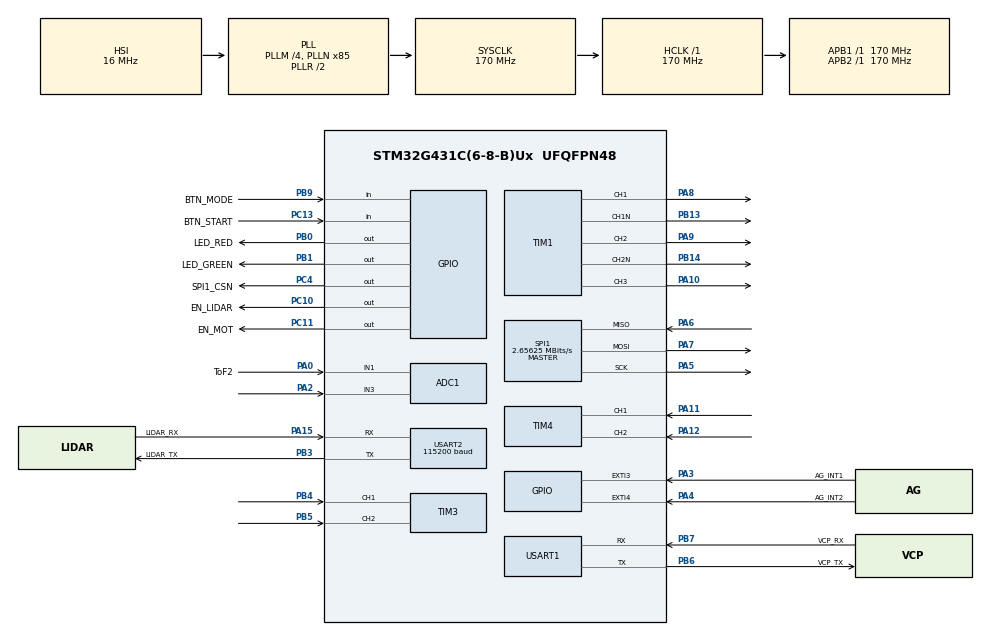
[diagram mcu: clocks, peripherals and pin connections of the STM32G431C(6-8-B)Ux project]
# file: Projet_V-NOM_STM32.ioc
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ADC1.Channel-1\#ChannelRegularConversion=ADC_CHANNEL_3
ADC1.ContinuousConvMode=ENABLE
ADC1.DMAContinuousRequests=DISABLE
ADC1.NbrOfConversion=1
ADC1.NbrOfConversionFlag=1
ADC1.OffsetNumber-1\#ChannelRegularConversion=ADC_OFFSET_NONE
ADC1.Rank-1\#ChannelRegularConversion=1
ADC1.SamplingTime-1\#ChannelRegularConversion=ADC_SAMPLETIME_2CYCLES_5
ADC1.master=1
Dma.Request0=USART2_RX
Dma.USART2_RX.0.Direction=DMA_PERIPH_TO_MEMORY
Dma.USART2_RX.0.EventEnable=DISABLE
Dma.USART2_RX.0.Instance=DMA1_Channel1
Dma.USART2_RX.0.MemDataAlignment=DMA_MDATAALIGN_BYTE
Dma.USART2_RX.0.MemInc=DMA_MINC_ENABLE
Dma.USART2_RX.0.Mode=DMA_CIRCULAR
Dma.USART2_RX.0.PeriphDataAlignment=DMA_PDATAALIGN_BYTE
Dma.USART2_RX.0.PeriphInc=DMA_PINC_DISABLE
Dma.USART2_RX.0.Polarity=HAL_DMAMUX_REQ_GEN_RISING
Dma.USART2_RX.0.Priority=DMA_PRIORITY_VERY_HIGH
Dma.USART2_RX.0.RequestNumber=1
Dma.USART2_RX.0.SignalID=NONE
Dma.USART2_RX.0.SyncEnable=DISABLE
Dma.USART2_RX.0.SyncPolarity=HAL_DMAMUX_SYNC_NO_EVENT
Dma.USART2_RX.0.SyncRequestNumber=1
Dma.USART2_RX.0.SyncSignalID=NONE
FREERTOS.Tasks01=defaultTask,0,128,StartDefaultTask,Default,NULL,Dynamic,NULL,NULL
FREERTOS.configTOTAL_HEAP_SIZE=10 * 1024
FREERTOS.configUSE_NEWLIB_REENTRANT=1
Mcu.Family=STM32G4
Mcu.Name=STM32G431C(6-8-B)Ux
Mcu.Package=UFQFPN48
NVIC.DMA1_Channel1_IRQn=true\:5\:0\:false\:false\:true\:true\:false\:true\:true
NVIC.PriorityGroup=NVIC_PRIORITYGROUP_4
NVIC.SPI1_IRQn=true\:5\:0\:false\:false\:true\:true\:true\:true\:true
NVIC.TIM2_IRQn=true\:15\:0\:false\:false\:true\:false\:false\:true\:true
NVIC.TimeBase=TIM2_IRQn
NVIC.TimeBaseIP=TIM2
NVIC.USART2_IRQn=true\:5\:0\:false\:false\:true\:true\:true\:true\:true
PA0.GPIO_Label=ToF2
PA0.Signal=SharedAnalog_PA0
PA10.Signal=S_TIM1_CH3
PA11.Signal=S_TIM4_CH1
PA12.Signal=S_TIM4_CH2
PA13.Mode=Serial_Wire
PA13.Signal=SYS_JTMS-SWDIO
PA14.Mode=Serial_Wire
PA14.Signal=SYS_JTCK-SWCLK
PA15.GPIO_Label=LIDAR_RX
PA15.Mode=Asynchronous
PA15.Signal=USART2_RX
PA2.Mode=IN3-Single-Ended
PA2.Signal=ADC1_IN3
PA3.GPIO_Label=AG_INT1
PA3.Signal=GPXTI3
PA4.GPIO_Label=AG_INT2
PA4.Signal=GPXTI4
PA5.Mode=Full_Duplex_Master
PA5.Signal=SPI1_SCK
PA6.Mode=Full_Duplex_Master
PA6.Signal=SPI1_MISO
PA7.Mode=Full_Duplex_Master
PA7.Signal=SPI1_MOSI
PA8.Signal=S_TIM1_CH1
PA9.Signal=S_TIM1_CH2
PB0.GPIO_Label=LED_RED
PB0.Signal=GPIO_Output
PB1.GPIO_Label=LED_GREEN
PB1.Signal=GPIO_Output
PB13.Mode=PWM Generation1 CH1 CH1N
PB13.Signal=TIM1_CH1N
PB14.Mode=PWM Generation2 CH2 CH2N
PB14.Signal=TIM1_CH2N
PB3.GPIO_Label=LIDAR_TX
PB3.Mode=Asynchronous
PB3.Signal=USART2_TX
PB4.Signal=S_TIM3_CH1
PB5.Signal=S_TIM3_CH2
PB6.GPIO_Label=VCP_TX
PB6.Mode=Asynchronous
PB6.Signal=USART1_TX
PB7.GPIO_Label=VCP_RX
PB7.Mode=Asynchronous
PB7.Signal=USART1_RX
PB9.GPIO_Label=BTN_MODE
PB9.Signal=GPIO_Input
PC10.GPIO_Label=EN_LIDAR
PC10.Signal=GPIO_Output
PC11.GPIO_Label=EN_MOT
PC11.Signal=GPIO_Output
PC13.GPIO_Label=BTN_START
PC13.Signal=GPIO_Input
PC14-OSC32_IN.Mode=LSE-External-Oscillator
PC14-OSC32_IN.Signal=RCC_OSC32_IN
PC15-OSC32_OUT.Mode=LSE-External-Oscillator
PC15-OSC32_OUT.Signal=RCC_OSC32_OUT
PC4.GPIO_Label=SPI1_CSN
PC4.Signal=GPIO_Output
PF0-OSC_IN.Mode=HSE-External-Oscillator
PF0-OSC_IN.Signal=RCC_OSC_IN
PF1-OSC_OUT.Mode=HSE-External-Oscillator
PF1-OSC_OUT.Signal=RCC_OSC_OUT
ProjectManager.HeapSize=0x200
ProjectManager.StackSize=0x400
ProjectManager.TargetToolchain=STM32CubeIDE
RCC.ADC12Freq_Value=170000000
RCC.AHBFreq_Value=170000000
RCC.APB1Freq_Value=170000000
RCC.APB1TimFreq_Value=170000000
RCC.APB2Freq_Value=170000000
RCC.APB2TimFreq_Value=170000000
RCC.CortexFreq_Value=170000000
RCC.EXTERNAL_CLOCK_VALUE=12288000
RCC.HCLKFreq_Value=170000000
RCC.HSE_VALUE=16000000
RCC.HSI48_VALUE=48000000
RCC.HSI_VALUE=16000000
RCC.PLLM=RCC_PLLM_DIV4
RCC.PLLN=85
RCC.SYSCLKFreq_VALUE=170000000
RCC.SYSCLKSource=RCC_SYSCLKSOURCE_PLLCLK
RCC.USBFreq_Value=170000000
RCC.VCOOutputFreq_Value=340000000
SH.S_TIM1_CH1.0=TIM1_CH1,PWM Generation1 CH1 CH1N
SH.S_TIM1_CH2.0=TIM1_CH2,PWM Generation2 CH2 CH2N
SH.S_TIM1_CH3.0=TIM1_CH3,PWM Generation3 CH3
SH.S_TIM3_CH1.0=TIM3_CH1,Encoder_Interface
SH.S_TIM3_CH2.0=TIM3_CH2,Encoder_Interface
SH.S_TIM4_CH1.0=TIM4_CH1,Encoder_Interface
SH.S_TIM4_CH2.0=TIM4_CH2,Encoder_Interface
SH.SharedAnalog_PA0.0=GPIO_Analog
SH.SharedAnalog_PA0.1=ADC2_IN1
SH.SharedAnalog_PA0.2=ADC1_IN1,IN1-Single-Ended
SPI1.BaudRatePrescaler=SPI_BAUDRATEPRESCALER_64
SPI1.CalculateBaudRate=2.65625 MBits/s
SPI1.DataSize=SPI_DATASIZE_8BIT
SPI1.Direction=SPI_DIRECTION_2LINES
SPI1.Mode=SPI_MODE_MASTER
SPI1.VirtualType=VM_MASTER
TIM1.Channel-PWM\ Generation1\ CH1\ CH1N=TIM_CHANNEL_1
TIM1.Channel-PWM\ Generation2\ CH2\ CH2N=TIM_CHANNEL_2
TIM1.Channel-PWM\ Generation3\ CH3=TIM_CHANNEL_3
USART1.VirtualMode-Asynchronous=VM_ASYNC
USART2.AutoBaudRateEnableParam=UART_ADVFEATURE_AUTOBAUDRATE_DISABLE
USART2.BaudRate=115200
USART2.ClockPrescaler=PRESCALER_DIV1
USART2.Mode=MODE_RX
USART2.OneBitSampling=UART_ONE_BIT_SAMPLE_DISABLE
USART2.OverSampling=UART_OVERSAMPLING_16
USART2.StopBits=STOPBITS_1
USART2.VirtualMode-Asynchronous=VM_ASYNC
VP_FREERTOS_VS_CMSIS_V1.Mode=CMSIS_V1
VP_SYS_VS_DBSignals.Mode=DisableDeadBatterySignals
VP_SYS_VS_tim2.Mode=TIM2
VP_TIM1_VS_ClockSourceINT.Mode=Internal
board=custom

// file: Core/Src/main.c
/* USER CODE BEGIN Header */
/**
 ******************************************************************************
 * @file           : main.c
 * @brief          : Main program body
 ******************************************************************************
 * @attention
 *
 * Copyright (c) 2024 STMicroelectronics.
 * All rights reserved.
 *
 * This software is licensed under terms that can be found in the LICENSE file
 * in the root directory of this software component.
 * If no LICENSE file comes with this software, it is provided AS-IS.
 *
 ******************************************************************************
 */
/* USER CODE END Header */
#include "main.h"
#include "cmsis_os.h"
#include "adc.h"
#include "dma.h"
#include "spi.h"
#include "tim.h"
#include "usart.h"
#include "gpio.h"

/* USER CODE BEGIN Includes */
#include <stdio.h>
#include <stdlib.h>
#include "stm32g4xx_hal.h"

// Drivers
#include "../drivers/driver_Motor.h"
#include "../drivers/driver_GP2Y0A41SK0F.h"
#include "../drivers/driver_YLIDARX2.h"
#include "../drivers/driver_ADXL343.h"

/* USER CODE END Includes */

/* USER CODE BEGIN PD */
#define DEBUG 1 /**< Enable or disable debug logs */

#if DEBUG
#define DEBUG_PRINT(...) printf(__VA_ARGS__)
#else
#define DEBUG_PRINT(...)
#endif

#define STACK_SIZE 256
#define TASK_PRIORITY_MOTOR 10
#define TASK_PRIORITY_CONTROL 2

#define TOF_TRESHHOLD 40 /**< Threshhold for edge detection */

#define DEBOUNCE_DELAY_MS 50 /**< Debounce delay in milliseconds */

/* USER CODE END PD */

/* USER CODE BEGIN PV */
// Messages
char small_logo_msg[] ="\r\n"
		"       \\_______/\r\n"
		"   `.,-'\\_____/`-.,'\r\n"
		"    /`..'\\ _ /`.,'\\\r\n"
		"   /  /`.,' `.,'\\  \\\r\n"
		"__/__/__/V-NOM\\__\\__\\__\r\n"
		"  \\  \\  \\     /  /  /\r\n"
		"   \\  \\,'`._,'`./  /\r\n"
		"    \\,'`./___\\,'`./\r\n"
		"   ,'`-./_____\\,-'`.\r\n"
		"       /       \\ \r\n";

char big_logo_msg[] = "\r\n"
		"⠀⠀⠀⠀⠀⠀⠀⠀⢀⣀⣤⠤⠶⠶⠶⠤⠤⣤⣀\t\r\n"
		"⠀⠀⠀⠀⢀⣠⠶⠛⠉⠀⠀⠀⠀⠀⠀⠀⠀⠀⠈⠙⠳⢦⣀\t\r\n"
		"⠀⠀⠀⣰⠟⠁⠀⠀⠀⠀⠀⠀⠀⠀⠀⠀⠀⠀⠀⠀⠀⠀⠙⢷⡄\t\r\n"
		"⠀⠀⣰⠏⠀⢠⣶⠀⠀⠀⠀⠀⠀⠀⠀⠀⠀⠀⠀⠀⠀⣤⡀⠀⠹⣆\t\r\n"
		"⠀⢠⡏⠀⢠⠟⣧⠀⠀⠀⠀⠀⠀⠀⠀⠀⠀⠀⠀⠀⠀⣿⢳⡄⠀⢹⡄\t\r\n"
		"⠀⣾⠀⠀⡞⠀⢸⡀⠀⠀⠀⠀⠀⠀⠀⠀⠀⠀⠀⠀⣰⠇⠀⢷⠀⠈⣇\t\r\n"
		"⢠⡇⠀⢠⠇⠀⠀⠙⣆⠀⠀⠀⠀⠀⠀⠀⠀⠀⠀⣰⠋⠀⠀⠸⡆⠀⣿\t\r\n"
		"⢸⡇⠀⢸⠀⠀⠀⠀⠙⢦⡀⠀⠀⠀⠀⠀⠀⢀⡾⠃⠀⠀⠀⢰⠇⠀⣿\t\r\n"
		"⢸⡇⠀⢸⠀⠀⠀⠀⠀⠀⠳⣄⣰⡄⢰⣄⣰⠋⠀⠀⠀⠀⠀⢸⡀⠀⣿\t\r\n"
		"⠘⡇⠀⢸⠀⠀⠀⠀⠀⠀⠀⠈⢹⡇⢸⠉⠁⠀⠀⠀⠀⠀⠀⠈⡇⠀⡟\t\r\n"
		"⠀⢿⠀⠈⢧⡀⠀⠀⠀⠀⠀⠀⣾⠀⢸⣄⠀⠀⠀⠀⠀⠀⠀⡼⢁⢸⡇\t\r\n"
		"⠀⢸⠘⣆⠈⢧⠀⠀⠀⠀⣠⠴⠃⠀⠀⠙⢧⣀⠀⠀⠀⠀⡼⠀⡼⢸⡃⠀⠀⠀⠀⠀⢀\t\r\n"
		"⠀⣾⠀⢸⣆⠘⠷⠤⠴⠚⣁⣀⣤⣤⣤⣄⣀⠉⠙⠲⠴⠚⢡⣾⠇⠘⡇⠀⠀⠀⠀⠀⠈⢷⣤⡀\t\r\n"
		"⠀⢹⣆⠈⣿⣷⣾⡖⣾⠻⣟⣾⣏⣻⣹⡟⡟⣿⢳⣶⣶⣾⣿⡟⠀⢰⡇⠀⠀⠀⠀⠀⠀⠘⣇⢻⡄\t\r\n"
		"⠀⠀⠻⣄⢸⣿⡋⠹⠿⣿⣿⡿⢿⣿⡟⣿⢿⣿⡟⠹⠋⠙⡿⠁⣴⠟⠀⠀⠀⠀⠀⠀⠀⠀⣿⠀⣷\t\r\n"
		"⠀⠀⠀⠹⣶⣿⣿⣄⠀⢻⣘⣦⣼⣿⣴⣿⣼⣼⣇⡀⣰⣿⠃⣴⠏⠀⠀⠀⠀⠀⠀⠀⢀⣴⠏⢀⡏\t\r\n"
		"⠀⠀⠀⠀⠙⣿⢿⣿⣥⣾⠛⠉⠀⠀⠉⠙⢦⡀⠈⠙⢿⣇⣰⠃⠀⠀⠀⠀⣀⣀⡤⠶⠛⠁⢠⡾⠁\t\r\n"
		"⠀⠀⠀⠀⠀⠘⣿⠻⣿⢻⣦⠀⢀⡀⠀⠀⠀⠙⠀⠀⠀⠹⣇⠀⠀⢀⣴⠟⠉⠀⠀⢀⣠⡼⠋\t\r\n"
		"⠀⠀⠀⠀⠀⠀⠘⣿⢹⡾⢻⣇⣴⡿⠳⢦⣀⠀⠀⠀⠀⠀⠙⠳⠶⠛⠁⠀⠀⢀⡼⠋⠁\t\r\n"
		"⠀⠀⠀⠀⠀⠀⠀⠘⣿⠻⡎⢹⢿⣷⣶⣎⣿⣧⡀⠀⠀⠀⠀⠀⠀⠀⠀⠀⢀⡾⠁\t\r\n"
		"⠀⠀⠀⠀⠀⠀⠀⠀⠸⣆⠙⢾⣸⠙⡿⢿⣩⠏⢹⣦⣀⠀⠀⠀⠀⠀⢀⣴⠟⠁\t\r\n"
		"⠀⠀⠀⠀⠀⠀⠀⠀⠀⠹⣦⡀⠉⠉⠉⠉⠁⣰⠏⠀⠈⠉⠛⠒⠒⠛⠉⠁\t\r\n"
		"⠀⠀⠀⠀⠀⠀⠀⠀⠀⠀⠈⠉⠓⠒⠒⠒⠋⠁\t\r\n";

char jumbo_logo_msg[] = "\r\n"
		"⣿⣿⣿⣿⣿⣿⣿⠿⢻⣿⣿⣿⣿⣿⣿⣿⣿⣿⣿⣿⣿⣿⣿⣿⣿⣿⣿⣿⣿⣿⣿⡟⠻⣿⣿⣿⣿⣿⣿⣿\r\n"
		"⣿⣿⣿⣿⣿⠟⠁⢠⣿⣿⣿⣿⣿⣿⣿⣿⣿⣿⣿⣿⣿⣿⣿⣿⣿⣿⣿⣿⣿⣿⣿⡇⠀⠀⠙⣿⣿⣿⣿⣿\r\n"
		"⣿⣿⣿⣿⠃⠀⢀⣿⣿⣿⣿⣿⣿⣿⣿⣿⣿⣿⣿⣿⣿⣿⣿⣿⣿⣿⣿⣿⣿⣿⣿⣷⠀⠀⠀⠈⢻⣿⣿⣿\r\n"
		"⣿⣿⣟⠁⠀⠀⢸⣿⣿⣿⣿⣿⣿⣿⣿⣿⣿⣿⣿⣿⣿⣿⣿⣿⣿⣿⣿⣿⣿⣿⣿⠇⢀⡀⠀⠀⠈⢿⣿⣿\r\n"
		"⣿⣿⡏⠀⠀⠀⢸⣿⣿⣿⣿⣿⣿⣿⣿⣿⣿⣿⣿⣿⣿⣿⣿⣿⣿⣿⣿⣿⣿⣿⣿⣟⣼⣿⠀⠀⠀⠈⣿⣿\r\n"
		"⣿⣿⠀⠀⠀⠀⠸⣿⣿⣿⣿⣿⣿⣿⣿⣿⣿⣿⣿⣿⣿⣿⣿⣿⣿⣿⣿⣿⣿⣿⣿⣿⣿⡏⠀⠀⠀⠀⢹⣿\r\n"
		"⣿⡿⠀⠀⠀⠀⠀⢿⣿⣿⣿⣿⣿⣿⣿⣿⣿⣿⢿⣿⣿⣿⣿⣿⣿⣿⣿⣿⣿⣿⣿⣿⣿⠁⠀⠀⠀⠀⠈⣿\r\n"
		"⣿⡇⠀⠀⠀⠀⠀⠈⠉⠉⣻⣿⡿⣿⣿⣿⣿⢷⣺⣿⣿⣿⣿⣿⣿⣿⣿⣭⣭⣙⣿⠋⠁⠀⠀⠀⠀⠀⠀⣿\r\n"
		"⣿⡷⡶⠀⠀⠀⠀⠀⠀⠈⠋⠛⠻⠿⠿⣿⡟⢿⣿⣿⣿⣿⡿⠿⡿⡿⣿⣻⣿⡿⠁⠀⠀⠀⠀⠀⠀⠀⢸⣿\r\n"
		"⣿⣿⠀⠀⠀⠀⠀⠀⠀⠀⠀⠀⠰⠦⠐⠛⢻⣿⣿⣿⣿⣿⣇⣼⣿⣿⣿⣿⠋⠀⠀⠀⠀⠀⠀⠀⠀⠀⢸⣿\r\n"
		"⣿⣿⡄⠀⠀⠀⠀⠀⠀⠀⠀⠀⠀⠘⣿⣯⣽⣿⣿⣿⣿⣿⣿⣿⣿⣿⣿⠃⠀⠀⠀⠀⠀⠀⠀⠀⠀⠀⢸⣿\r\n"
		"⣿⣿⣇⠀⠀⠀⠀⠀⠀⠀⠀⠀⠀⠀⢸⡟⢿⣿⣿⣿⣿⣿⣿⣿⢃⣿⠇⠀⠀⠀⠀⠀⠀⠀⠀⠀⠀⢀⣿⣿\r\n"
		"⣿⣿⣿⡇⢀⣀⠀⠀⠀⠀⠀⠀⠀⠀⠈⠻⣮⣿⣿⣿⣿⣿⣿⡟⠿⠋⠀⠀⠀⠀⠀⠀⠀⠀⡀⠀⠀⣾⣿⣿\r\n"
		"⣿⣿⣿⡗⠈⣿⣿⣆⠀⠀⠀⠀⠀⠀⠀⠀⢀⡸⣿⣿⣿⣿⡏⠀⠀⠀⠀⠀⠀⠀⠀⠀⣰⣾⣧⡄⢀⣿⣿⣿\r\n"
		"⣿⣿⣿⣿⣤⣿⣿⣿⣷⣄⣀⣴⣶⣶⣶⣤⣄⣹⣿⣿⣿⣿⠀⠀⢀⣀⠶⣄⣀⣤⡶⠾⢿⣿⣿⣷⣿⣿⣿⣿\r\n"
		"⣿⣿⣿⣿⣿⣿⣿⣿⣿⡿⣿⣿⣿⣿⣿⣿⣿⣿⣿⣿⣿⣿⢺⣷⢿⣿⣾⣿⣿⣿⣿⣿⣿⣿⣿⣿⣿⣿⣿⣿\r\n"
		"⣿⣿⣿⣯⣿⠛⠃⣿⢹⢷⣿⣿⣿⣿⣿⣿⣿⣿⣿⣿⣿⣿⣾⣿⣾⣿⣿⣿⡿⣿⢿⠛⣿⣿⣿⣿⣿⣿⣿⣿\r\n"
		"⣿⣿⣿⣿⣿⣿⣧⡇⡈⢹⣿⠉⢿⠟⢻⡿⠿⣿⠯⢿⣿⣿⣿⣿⣿⣿⠛⢿⠁⢻⣾⡀⣉⣿⣿⣿⣿⣿⣿⣿\r\n"
		"⣿⣿⣿⣿⣿⣿⣿⣧⣧⢸⢸⠀⢸⠀⠀⠁⠀⢿⠀⢸⣿⠏⢹⡟⠀⣿⠀⢸⠀⣿⢹⣄⣿⣿⣿⣿⣿⣿⣿⣿\r\n"
		"⣿⣿⣿⣿⣿⣿⣿⣿⣿⣿⢸⡄⠘⠀⠀⠀⠀⣼⠀⠀⣿⠀⢨⡀⠀⢿⠀⢸⠀⣿⠘⢻⣿⣿⣿⣿⣿⣿⣿⣿\r\n"
		"⣿⣿⣿⣿⣿⣿⣿⣿⣿⣿⣿⣧⢸⡀⢸⡄⠀⣧⠀⢘⣿⠀⠀⣧⠀⢸⠀⣸⣸⣿⢿⣿⣿⣿⣿⣿⣿⣿⣿⣿\r\n"
		"⣿⣿⣿⣿⣿⣿⣿⣿⣿⣿⢿⣿⣿⣷⣸⣧⠀⣿⠀⢸⣿⡇⢠⡿⠀⣼⣻⣿⣿⠉⣾⣿⣿⣿⣿⣿⣿⣿⣿⣿\r\n"
		"⣿⣿⣿⣿⣿⣿⣿⣿⣿⡿⢸⣿⣿⣿⣿⣿⡆⣿⣆⢸⣿⡇⣼⡇⣸⣿⣿⣿⡟⠛⣿⣿⣿⣿⣿⣿⣿⣿⣿⣿\r\n"
		"⣿⣿⣿⣿⣿⣿⣿⣿⣿⣄⠀⣹⣿⣿⣿⣿⣿⣿⣿⣾⣿⣷⣿⣇⣿⣿⣿⣿⣿⣤⣿⣿⣿⣿⣿⣿⣿⣿⣿⣿\r\n"
		"⣿⣿⣿⣿⣿⣿⣿⣿⣿⣧⠀⠛⣿⣿⣿⣿⣿⣿⣿⣿⣿⣇⣿⣿⣿⣿⣿⡿⠙⠉⣿⣿⣿⣿⣿⣿⣿⣿⣿⣿\r\n"
		"⣿⣿⣿⣿⣿⣿⣿⣿⣿⣿⡇⠀⢿⣿⣿⣿⣿⣿⣿⣿⣿⣿⣿⣿⣿⣿⣿⣷⠀⢀⣿⣿⣿⣿⣿⣿⣿⣿⣿⣿\r\n"
		"⣿⣿⣿⣿⣿⣿⣿⣿⣿⣏⣷⠀⢸⢻⣿⢹⣿⣿⣿⢻⣿⣿⣿⣿⣿⣿⣿⠙⠀⢘⣿⣿⣿⣿⣿⣿⣿⣿⣿⣿\r\n"
		"⣿⣿⣿⣿⣿⣿⣿⣿⣿⣿⣿⡟⡏⠀⢿⢸⣿⣿⡟⢸⣿⣿⣿⡇⣿⣿⠹⠀⢠⣾⣿⣿⣿⣿⣿⣿⣿⣿⣿⣿\r\n"
		"⣿⣿⣿⣿⣿⣿⣿⣿⣿⣿⣿⣿⣷⣀⣸⠸⡏⢿⣇⠀⡙⠋⣿⡇⢸⡏⡇⠀⣾⣿⣿⣿⣿⣿⣿⣿⣿⣿⣿⣿\r\n"
		"⣿⣿⣿⣿⣿⣿⣿⣿⣿⣿⣿⡇⣿⡟⢹⠀⠁⠸⡇⠀⣤⠀⢿⠀⠸⠁⣆⣠⣿⣿⣿⣿⣿⣿⣿⣿⣿⣿⣿⣿\r\n"
		"⣿⣿⣿⣿⣿⣿⣿⣿⣿⣿⣿⣷⣿⣷⣾⣄⣷⠀⣷⠀⣿⠀⢸⡇⣆⣰⣿⣿⣿⣿⣿⣿⣿⣿⣿⣿⣿⣿⣿⣿\r\n"
		"⣿⣿⣿⣿⣿⣿⣿⣿⣿⣿⣿⣿⣿⣿⣿⣿⣿⣧⣿⣤⣿⣧⣾⣿⣿⣿⣿⣿⣿⣿⣿⣿⣿⣿⣿⣿⣿⣿⣿⣿\r\n";

// Global YLIDAR X2 handler
h_YLIDARX2_t hlidar;

// Global Motors handler
h_Motor_t hMotors;

// Global ToF sensors handler
h_GP2Y0A41SK0F_t hTof;

// Global ADXL343 (Accelerometer) handler
h_ADXL343_t hADXL;

// Task handles
TaskHandle_t xMotors;
TaskHandle_t xControl;
SemaphoreHandle_t xMutex;

// Buttons variables
volatile uint8_t buttonStartPressed = 1; /**< Flag to indicate button press state */

/* USER CODE END PV */

void SystemClock_Config(void);
void MX_FREERTOS_Init(void);

/* USER CODE BEGIN 0 */
/**
 * @brief Transmit a character over UART.
 * @param ch: Character to transmit.
 * @retval int: The transmitted character.
 */
int __io_putchar(int ch)
{
	HAL_UART_Transmit(&huart1, (uint8_t*)&ch, 1, HAL_MAX_DELAY);

	return ch;
}

/**
 * @brief Interrupt callbacks.
 * @details Contains interrupt service routines (ISRs) and related callbacks.
 */

/**
 * @brief UART receive half-complete callback.
 * @param huart: Pointer to the UART handle.
 * @retval None
 * @details This callback processes partial DMA reception for the UART instance
 * (e.g., used for YLIDAR data).
 */
void HAL_UART_RxHalfCpltCallback(UART_HandleTypeDef *huart) {
	if (huart->Instance == USART2) {
		YLIDARX2_ProcessDMAHalfComplete(&hlidar);
	}
}

/**
 * @brief UART receive complete callback.
 * @param huart: Pointer to the UART handle.
 * @retval None
 * @details This callback processes complete DMA reception for the UART instance.
 */
void HAL_UART_RxCpltCallback(UART_HandleTypeDef *huart) {
	if (huart->Instance == USART2) {
		YLIDARX2_ProcessDMAComplete(&hlidar);
	}
}

/**
 * @brief GPIO interrupt callback for EXTI line.
 * @param GPIO_Pin: The GPIO pin that triggered the interrupt.
 * @retval None
 * @details This callback handles the interrupt triggered by the accelerometer
 * (single tap or other configured events).
 */
void HAL_GPIO_EXTI_Callback(uint16_t GPIO_Pin)
{
	if (GPIO_Pin == AG_INT1_Pin) // Interrupt triggered by INT1
	{
		uint8_t int_source;
		ADXL343_readRegister(ADXL343_INT_SOURCE, &int_source, 1);

		if (int_source & 0x40) // Check SINGLE_TAP bit
		{
			DEBUG_PRINT("Single Tap Detected!\n");
			Motor_Stop(&hMotors);
			vTaskDelete(xControl);
		}
	}
	else if (GPIO_Pin == AG_INT2_Pin) // Interrupt triggered by INT2
	{
		DEBUG_PRINT("Interrupt triggered on INT2\n");
		// Handle other potential events from INT2 if needed
	}
	else if (GPIO_Pin == BTN_START_Pin)	// Check if the interrupt is from BTN_START
	{
		static uint32_t last_interrupt_time = 0;
		uint32_t current_time = HAL_GetTick();

		// Debounce handling
		if ((current_time - last_interrupt_time) > DEBOUNCE_DELAY_MS) {
			buttonStartPressed++; // Set flag for button press
			last_interrupt_time = current_time;
		}
	}
}

/**
 * @brief Task declarations.
 * @details Contains declarations for FreeRTOS tasks in the system.
 */

/**
 * @brief Motor control task.
 * @param unsused: Unused parameter.
 * @retval None
 * @details This FreeRTOS task continuously updates the motor speed based on current settings.
 */
void task_Motors(void * unsused)
{
	DEBUG_PRINT("task_Motors\r\n");

	while (1)
	{
		GP2Y0A41SK0F_get_distance(&hTof);
		Motor_UpdateSpeed(&hMotors);

		vTaskDelay(1);
	}
}

/**
 * @brief Behavior control task.
 * @param unsused: Unused parameter.
 * @retval None
 * @details This FreeRTOS task controls motor behavior based on ToF sensor readings.
 * It evaluates distances from ToF sensors and adjusts motor directions accordingly.
 */
void task_Control(void * unsused)
{
	DEBUG_PRINT("task_Control\r\n");

	while (1)
	{
		DEBUG_PRINT("ToF1 distance: %d mm, ToF2 distance: %d mm\r\n", hTof.distance_tof1, hTof.distance_tof2);

		/* Motors test */
		if (hTof.distance_tof2 > TOF_TRESHHOLD && hTof.distance_tof1 > TOF_TRESHHOLD)
		{
			hMotors.mode_mot1 = FORWARD_MODE;
			hMotors.mode_mot2 = FORWARD_MODE;
		}
		else if (hTof.distance_tof2 > TOF_TRESHHOLD && hTof.distance_tof1 <= TOF_TRESHHOLD)
		{
			hMotors.mode_mot1 = FORWARD_MODE;
			hMotors.mode_mot2 = REVERSE_MODE;
		}
		else if (hTof.distance_tof2 <= TOF_TRESHHOLD && hTof.distance_tof1 > TOF_TRESHHOLD)
		{
			hMotors.mode_mot1 = REVERSE_MODE;
			hMotors.mode_mot2 = FORWARD_MODE;
		}
		else //if (hTof.distance_tof2 <= TOF_TRESHHOLD && hTof.distance_tof1 <= TOF_TRESHHOLD)
		{
			hMotors.mode_mot1 = REVERSE_MODE;
			hMotors.mode_mot2 = REVERSE_MODE;
		}

		Motor_SetMode(&hMotors);
		Motor_SetSpeed_percent(&hMotors, 40, 40);
		DEBUG_PRINT("Mot1 speed: %d, Mot2 speed: %d\r\n", hMotors.current_speed1, hMotors.current_speed2);

		vTaskDelay(1);
	}
}

/**
 * @brief Handles errors during task creation.
 * @param r: Return value from xTaskCreate.
 * @retval None
 * @details This function checks the return value of `xTaskCreate` to determine
 * if a task was created successfully. In case of failure, it performs error handling.
 */
void errHandler_xTaskCreate(BaseType_t r)
{
	/* Vérification si la tâche a été créée avec succès */
	if (pdPASS == r) {
		/* Si la tâche est créée avec succès, démarrer le scheduler */
		DEBUG_PRINT("Tâche crée avec succès\r\n");
	} else if (errCOULD_NOT_ALLOCATE_REQUIRED_MEMORY == r) {
		DEBUG_PRINT("Erreur: Mémoire insuffisante\r\n");
		Error_Handler();
	} else {
		/* Cas improbable : code d'erreur non prévu pour xTaskCreate */
		DEBUG_PRINT("Erreur inconnue lors de la création de la tâche\r\n");
		Error_Handler();  	// Gestion d'erreur générique
		NVIC_SystemReset(); // Réinitialiser le microcontrôleur
	}
}

/* USER CODE END 0 */

int main(void)
{

	/* USER CODE BEGIN 1 */
	BaseType_t xReturned;

	/* USER CODE END 1 */

	/* MCU Configuration--------------------------------------------------------*/

	/* Reset of all peripherals, Initializes the Flash interface and the Systick. */
	HAL_Init();

	/* Configure the system clock */
	SystemClock_Config();

	/* USER CODE BEGIN SysInit */
	/**
	 * @brief Peripheral initialization.
	 * @details Contains initialization code for GPIO, ADC, SPI, TIM, etc.
	 */
	/* USER CODE END SysInit */

	/* Initialize all configured peripherals */
	MX_GPIO_Init();
	MX_DMA_Init();
	MX_SPI1_Init();
	MX_TIM1_Init();
	MX_TIM3_Init();
	MX_TIM4_Init();
	MX_USART2_UART_Init();
	MX_USART1_UART_Init();
	MX_ADC1_Init();
	/* USER CODE BEGIN 2 */
	DEBUG_PRINT("\r\n*** Waking up V-NOM ***\r\n");
	DEBUG_PRINT("%s", jumbo_logo_msg);

	/* ToF sensors Initialization */
	GP2Y0A41SK0F_Init(&hTof);

	/* ADXL343 Initialization */
	ADXL343_Init(&hADXL);

	/* Motors Initialization */
	Motor_Init(&hMotors, &htim1);

	/* YLIDAR X2 Initialization with DMA */
	LIDAR_RX_GPIO_Port->PUPDR = GPIO_PULLUP;
	YLIDARX2_InitDMA(&hlidar, &huart2);

	xMutex = xSemaphoreCreateMutex();
	if (xMutex == NULL) {
		printf("Erreur lors de la création du Mutex\r\n");
		Error_Handler();
	}

	/* Motors task */
	xReturned = xTaskCreate(
			task_Motors, // Function that implements the task.
			"task_Motors", // Text name for the task.
			STACK_SIZE, // Stack size in words, not bytes.
			(void *) 0, // Parameter passed into the task.
			TASK_PRIORITY_MOTOR,// Priority at which the task is created.
			&xMotors); // Used to pass out the created task's handle.

	errHandler_xTaskCreate(xReturned);

	/* Control task */
	xReturned = xTaskCreate(
			task_Control, // Function that implements the task.
			"task_Control", // Text name for the task.
			STACK_SIZE, // Stack size in words, not bytes.
			(void *) 0, // Parameter passed into the task.
			TASK_PRIORITY_CONTROL,// Priority at which the task is created.
			&xControl); // Used to pass out the created task's handle.

	errHandler_xTaskCreate(xReturned);

	/* USER CODE END 2 */

	/* Call init function for freertos objects (in cmsis_os2.c) */
	MX_FREERTOS_Init();

	/* Start scheduler */
	osKernelStart();

	/* We should never get here as control is now taken by the scheduler */

	/* Infinite loop */
	/* USER CODE BEGIN WHILE */
	while (1)
	{
		/* ADXL343 test *
		ADXL343_get_Acceleration(&hADXL);*/

		/* USER CODE END WHILE */

	}
}

void SystemClock_Config(void)
{
	RCC_OscInitTypeDef RCC_OscInitStruct = {0};
	RCC_ClkInitTypeDef RCC_ClkInitStruct = {0};

	/** Configure the main internal regulator output voltage
	 */
	HAL_PWREx_ControlVoltageScaling(PWR_REGULATOR_VOLTAGE_SCALE1_BOOST);

	/** Initializes the RCC Oscillators according to the specified parameters
	 * in the RCC_OscInitTypeDef structure.
	 */
	RCC_OscInitStruct.OscillatorType = RCC_OSCILLATORTYPE_HSI;
	RCC_OscInitStruct.HSIState = RCC_HSI_ON;
	RCC_OscInitStruct.HSICalibrationValue = RCC_HSICALIBRATION_DEFAULT;
	RCC_OscInitStruct.PLL.PLLState = RCC_PLL_ON;
	RCC_OscInitStruct.PLL.PLLSource = RCC_PLLSOURCE_HSI;
	RCC_OscInitStruct.PLL.PLLM = RCC_PLLM_DIV4;
	RCC_OscInitStruct.PLL.PLLN = 85;
	RCC_OscInitStruct.PLL.PLLP = RCC_PLLP_DIV2;
	RCC_OscInitStruct.PLL.PLLQ = RCC_PLLQ_DIV2;
	RCC_OscInitStruct.PLL.PLLR = RCC_PLLR_DIV2;
	if (HAL_RCC_OscConfig(&RCC_OscInitStruct) != HAL_OK)
	{
		Error_Handler();
	}

	/** Initializes the CPU, AHB and APB buses clocks
	 */
	RCC_ClkInitStruct.ClockType = RCC_CLOCKTYPE_HCLK|RCC_CLOCKTYPE_SYSCLK
			|RCC_CLOCKTYPE_PCLK1|RCC_CLOCKTYPE_PCLK2;
	RCC_ClkInitStruct.SYSCLKSource = RCC_SYSCLKSOURCE_PLLCLK;
	RCC_ClkInitStruct.AHBCLKDivider = RCC_SYSCLK_DIV1;
	RCC_ClkInitStruct.APB1CLKDivider = RCC_HCLK_DIV1;
	RCC_ClkInitStruct.APB2CLKDivider = RCC_HCLK_DIV1;

	if (HAL_RCC_ClockConfig(&RCC_ClkInitStruct, FLASH_LATENCY_4) != HAL_OK)
	{
		Error_Handler();
	}
}

/* USER CODE BEGIN 4 */

/**
 * @brief UART error callback.
 * @param huart: Pointer to the UART handle.
 * @retval None
 * @details This function handles UART errors such as parity, noise, framing,
 * or overrun errors. It restarts the LIDAR's DMA in case of errors.
 */
void HAL_UART_ErrorCallback(UART_HandleTypeDef *huart)
{
	if (huart->Instance == USART2)
	{
		if (HAL_UART_GetError(huart) & HAL_UART_ERROR_PE)
			DEBUG_PRINT("Parity Error!\r\n");
		if (HAL_UART_GetError(huart) & HAL_UART_ERROR_NE)
			DEBUG_PRINT("Noise Error!\r\n");
		if (HAL_UART_GetError(huart) & HAL_UART_ERROR_FE)
			DEBUG_PRINT("Framing Error!\r\n");
		if (HAL_UART_GetError(huart) & HAL_UART_ERROR_ORE)
			DEBUG_PRINT("Overrun Error!\r\n");

		//YLIDARX2_RestartDMA(&hlidar);
	}
}

/* USER CODE END 4 */

void HAL_TIM_PeriodElapsedCallback(TIM_HandleTypeDef *htim)
{
	if (htim->Instance == TIM2) {
		HAL_IncTick();
	}
}

void Error_Handler(void)
{
	__disable_irq();
	while (1)
	{
	}
}
